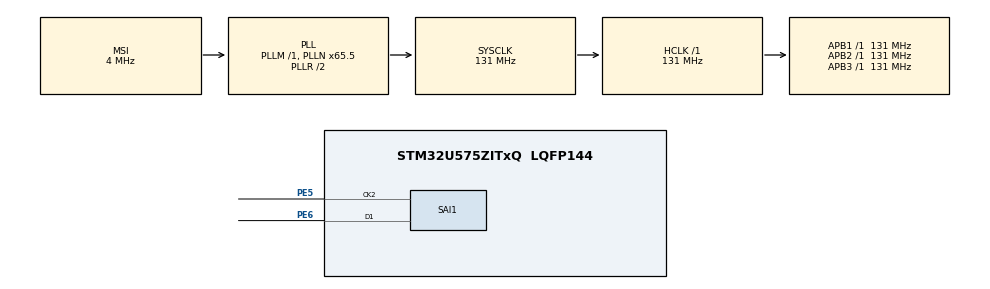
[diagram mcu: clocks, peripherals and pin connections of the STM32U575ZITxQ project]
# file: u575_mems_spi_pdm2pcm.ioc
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CORTEX_M33_NS.userName=CORTEX_M33
GPDMA1.CIRCULARMODE_GPDMACH0=ENABLE
GPDMA1.DESTINC_GPDMACH0=DMA_DINC_INCREMENTED
GPDMA1.IPHANDLE_GPDMACH0-SIMPLEREQUEST_GPDMACH0=__NULL
GPDMA1.REQUEST_GPDMACH0=GPDMA1_REQUEST_SAI1_A
Mcu.Family=STM32U5
Mcu.Name=STM32U575ZITxQ
Mcu.Package=LQFP144
NVIC.GPDMA1_Channel0_IRQn=true\:0\:0\:false\:false\:true\:false\:true\:true
NVIC.PriorityGroup=NVIC_PRIORITYGROUP_4
PE5.Mode=PDM_Master_Mode_CK2
PE5.Signal=SAI1_CK2
PE6.Mode=PDM_Master_Mode_CK2
PE6.Signal=SAI1_D1
ProjectManager.HeapSize=0x200
ProjectManager.StackSize=0x400
ProjectManager.TargetToolchain=STM32CubeIDE
RCC.ADCFreq_Value=16000000
RCC.AHBFreq_Value=131000000
RCC.APB1Freq_Value=131000000
RCC.APB1TimFreq_Value=131000000
RCC.APB2Freq_Value=131000000
RCC.APB2TimFreq_Value=131000000
RCC.APB3Freq_Value=131000000
RCC.CortexFreq_Value=131000000
RCC.EPOD_VALUE=4000000
RCC.HCLKFreq_Value=131000000
RCC.HSE_VALUE=16000000
RCC.HSI48_VALUE=48000000
RCC.HSI_VALUE=16000000
RCC.LSE_VALUE=32768
RCC.LSIDIV_VALUE=32000
RCC.MSI_VALUE=4000000
RCC.PLL2N=80
RCC.PLLFRACN=4096
RCC.PLLN=65
RCC.SPI1CLockSelection=RCC_SPI1CLKSOURCE_PCLK2
RCC.SYSCLKFreq_VALUE=131000000
RCC.SYSCLKSource=RCC_SYSCLKSOURCE_PLLCLK
RCC.USBFreq_Value=48000000
RCC.VCOOutputFreq_Value=262000000
SAI1.Activation=ENABLE
SAI1.ErrorAudioFreq-PDM_Master_Mode_CK2=62.76 %
SAI1.FSPolarity-PDM_Master_Mode_CK2=SAI_FS_ACTIVE_HIGH
SAI1.FrameLength-PDM_Master_Mode_CK2=16
SAI1.Instance-PDM_Master_Mode_CK2=SAI$Index_Block_A
SAI1.MckOutput-PDM_Master_Mode_CK2=SAI_MCK_OUTPUT_DISABLE
SAI1.MonoStereoMode-PDM_Master_Mode_CK2=SAI_STEREOMODE
SAI1.RealAudioFreq-PDM_Master_Mode_CK2=312.5 KHz
SAI1.SlotActive-PDM_Master_Mode_CK2=0x00000001
SAI1.SlotNumber-PDM_Master_Mode_CK2=2
SAI1.VirtualMode-PDM_Master_Mode_CK2=VM_MASTER
SAI1.VirtualProtocol-PDM_Master_Mode_CK2=VM_PDM_PROTOCOL
SAI1.VirtualSlotActive-PDM_Master_Mode_CK2=SAI_SLOT_USERSETTING
SAI1.VirtualSlotActive0-PDM_Master_Mode_CK2=true
VP_CRC_VS_CRC.Mode=CRC_Activate
VP_GPDMA1_VS_GPDMACH0.Mode=SIMPLEREQUEST_GPDMACH0
VP_LPBAMQUEUE_VS_QUEUE.Mode=QUEUEMODE
VP_LPBAM_VS_SIG1.Mode=SmartRun
VP_LPBAM_VS_SIG4.Mode=LPDMA1
VP_MEMORYMAP_VS_MEMORYMAP.Mode=CurAppReg
VP_PWR_VS_SECSignals.Mode=Security/Privilege
board=custom

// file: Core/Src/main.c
/* USER CODE BEGIN Header */
/**
 ******************************************************************************
 * @file           : main.c
 * @brief          : Main program body
 ******************************************************************************
 * @attention
 *
 * Copyright (c) 2024 STMicroelectronics.
 * All rights reserved.
 *
 * This software is licensed under terms that can be found in the LICENSE file
 * in the root directory of this software component.
 * If no LICENSE file comes with this software, it is provided AS-IS.
 *
 ******************************************************************************
 */
/* USER CODE END Header */
#include "main.h"

/* USER CODE BEGIN Includes */
#include "pdm2pcm.h"
/* USER CODE END Includes */

/* USER CODE BEGIN PD */

// output buffer buffer step in bytes

// input buffer in bytes 48samples * 64 decimation / 8bits
#define STEP_IN (STEP_OUT * 64 / 8)

#define PCM_SIZE 16384 * STEP_OUT

/* USER CODE END PD */

CRC_HandleTypeDef hcrc;

SAI_HandleTypeDef hsai_BlockA1;
DMA_NodeTypeDef Node_GPDMA1_Channel0;
DMA_QListTypeDef List_GPDMA1_Channel0;
DMA_HandleTypeDef handle_GPDMA1_Channel0;

/* USER CODE BEGIN PV */
extern PDM_Filter_Handler_t PDM1_filter_handler;

uint8_t u8SpiRxBuf[STEP_IN * 2];

uint16_t u16PcmBuf[PCM_SIZE];

uint32_t input_ptr = 0;
uint32_t output_ptr = 0;
uint32_t i;
uint32_t ret_val;
/* USER CODE END PV */

void SystemClock_Config(void);
static void MX_GPIO_Init(void);
static void MX_GPDMA1_Init(void);
static void MX_CRC_Init(void);
static void MX_SAI1_Init(void);

/* USER CODE BEGIN 0 */
// void HAL_SPI_RxHalfCpltCallback(SPI_HandleTypeDef *hspi)
void HAL_SAI_RxHalfCpltCallback(SAI_HandleTypeDef *hsai)
{
  ret_val = PDM_Filter((uint8_t *)(&u8SpiRxBuf[0]), &u16PcmBuf[output_ptr], &PDM1_filter_handler);
  output_ptr += STEP_OUT;
  if (output_ptr >= PCM_SIZE)
  {
    while (1)
      ;
  }
}
void HAL_SAI_RxCpltCallback(SAI_HandleTypeDef *hsai)
// void HAL_SPI_RxCpltCallback(SPI_HandleTypeDef *hspi)
{
  ret_val = PDM_Filter((uint8_t *)(&u8SpiRxBuf[STEP_IN]), &u16PcmBuf[output_ptr], &PDM1_filter_handler);
  output_ptr += STEP_OUT;

  if (output_ptr >= PCM_SIZE)
  {
    while (1)
      ;
  }
}
/* USER CODE END 0 */

int main(void)
{

  /* MCU Configuration--------------------------------------------------------*/

  /* Reset of all peripherals, Initializes the Flash interface and the Systick. */
  HAL_Init();

  /* Configure the system clock */
  SystemClock_Config();

  /* Initialize all configured peripherals */
  MX_GPIO_Init();
  MX_GPDMA1_Init();
  MX_CRC_Init();
  MX_SAI1_Init();
  /* USER CODE BEGIN 2 */
  MX_CRC_Init();
  /* USER CODE BEGIN 2 */
  MX_PDM2PCM_Init();

  // HAL_SPI_Receive_DMA(&hspi1, u8SpiRxBuf, STEP_IN * 2);
  HAL_SAI_Receive_DMA(&hsai_BlockA1, u8SpiRxBuf, STEP_IN * 2);
  /* USER CODE END 2 */

  /* Infinite loop */
  while (1)
  {

  }
}

void SystemClock_Config(void)
{
  RCC_OscInitTypeDef RCC_OscInitStruct = {0};
  RCC_ClkInitTypeDef RCC_ClkInitStruct = {0};

  /** Configure the main internal regulator output voltage
  */
  if (HAL_PWREx_ControlVoltageScaling(PWR_REGULATOR_VOLTAGE_SCALE1) != HAL_OK)
  {
    Error_Handler();
  }

  /** Initializes the CPU, AHB and APB buses clocks
  */
  RCC_OscInitStruct.OscillatorType = RCC_OSCILLATORTYPE_MSI;
  RCC_OscInitStruct.MSIState = RCC_MSI_ON;
  RCC_OscInitStruct.MSICalibrationValue = RCC_MSICALIBRATION_DEFAULT;
  RCC_OscInitStruct.MSIClockRange = RCC_MSIRANGE_4;
  RCC_OscInitStruct.PLL.PLLState = RCC_PLL_ON;
  RCC_OscInitStruct.PLL.PLLSource = RCC_PLLSOURCE_MSI;
  RCC_OscInitStruct.PLL.PLLMBOOST = RCC_PLLMBOOST_DIV1;
  RCC_OscInitStruct.PLL.PLLM = 1;
  RCC_OscInitStruct.PLL.PLLN = 65;
  RCC_OscInitStruct.PLL.PLLP = 2;
  RCC_OscInitStruct.PLL.PLLQ = 2;
  RCC_OscInitStruct.PLL.PLLR = 2;
  RCC_OscInitStruct.PLL.PLLRGE = RCC_PLLVCIRANGE_0;
  RCC_OscInitStruct.PLL.PLLFRACN = 4096;
  if (HAL_RCC_OscConfig(&RCC_OscInitStruct) != HAL_OK)
  {
    Error_Handler();
  }

  /** Initializes the CPU, AHB and APB buses clocks
  */
  RCC_ClkInitStruct.ClockType = RCC_CLOCKTYPE_HCLK|RCC_CLOCKTYPE_SYSCLK
                              |RCC_CLOCKTYPE_PCLK1|RCC_CLOCKTYPE_PCLK2
                              |RCC_CLOCKTYPE_PCLK3;
  RCC_ClkInitStruct.SYSCLKSource = RCC_SYSCLKSOURCE_PLLCLK;
  RCC_ClkInitStruct.AHBCLKDivider = RCC_SYSCLK_DIV1;
  RCC_ClkInitStruct.APB1CLKDivider = RCC_HCLK_DIV1;
  RCC_ClkInitStruct.APB2CLKDivider = RCC_HCLK_DIV1;
  RCC_ClkInitStruct.APB3CLKDivider = RCC_HCLK_DIV1;

  if (HAL_RCC_ClockConfig(&RCC_ClkInitStruct, FLASH_LATENCY_4) != HAL_OK)
  {
    Error_Handler();
  }
}

static void MX_CRC_Init(void)
{

  hcrc.Instance = CRC;
  hcrc.Init.DefaultPolynomialUse = DEFAULT_POLYNOMIAL_ENABLE;
  hcrc.Init.DefaultInitValueUse = DEFAULT_INIT_VALUE_ENABLE;
  hcrc.Init.InputDataInversionMode = CRC_INPUTDATA_INVERSION_NONE;
  hcrc.Init.OutputDataInversionMode = CRC_OUTPUTDATA_INVERSION_DISABLE;
  hcrc.InputDataFormat = CRC_INPUTDATA_FORMAT_BYTES;
  if (HAL_CRC_Init(&hcrc) != HAL_OK)
  {
    Error_Handler();
  }

}

static void MX_GPDMA1_Init(void)
{

  /* Peripheral clock enable */
  __HAL_RCC_GPDMA1_CLK_ENABLE();

  /* GPDMA1 interrupt Init */
    HAL_NVIC_SetPriority(GPDMA1_Channel0_IRQn, 0, 0);
    HAL_NVIC_EnableIRQ(GPDMA1_Channel0_IRQn);

}

static void MX_SAI1_Init(void)
{

  hsai_BlockA1.Instance = SAI1_Block_A;
  hsai_BlockA1.Init.Protocol = SAI_FREE_PROTOCOL;
  hsai_BlockA1.Init.AudioMode = SAI_MODEMASTER_RX;
  hsai_BlockA1.Init.DataSize = SAI_DATASIZE_8;
  hsai_BlockA1.Init.FirstBit = SAI_FIRSTBIT_MSB;
  hsai_BlockA1.Init.ClockStrobing = SAI_CLOCKSTROBING_FALLINGEDGE;
  hsai_BlockA1.Init.Synchro = SAI_ASYNCHRONOUS;
  hsai_BlockA1.Init.OutputDrive = SAI_OUTPUTDRIVE_DISABLE;
  hsai_BlockA1.Init.NoDivider = SAI_MASTERDIVIDER_ENABLE;
  hsai_BlockA1.Init.FIFOThreshold = SAI_FIFOTHRESHOLD_EMPTY;
  hsai_BlockA1.Init.AudioFrequency = 256000;
  hsai_BlockA1.Init.MckOutput = SAI_MCK_OUTPUT_DISABLE;
  hsai_BlockA1.Init.MonoStereoMode = SAI_STEREOMODE;
  hsai_BlockA1.Init.CompandingMode = SAI_NOCOMPANDING;
  hsai_BlockA1.Init.PdmInit.Activation = ENABLE;
  hsai_BlockA1.Init.PdmInit.MicPairsNbr = 1;
  hsai_BlockA1.Init.PdmInit.ClockEnable = SAI_PDM_CLOCK2_ENABLE;
  hsai_BlockA1.FrameInit.FrameLength = 16;
  hsai_BlockA1.FrameInit.ActiveFrameLength = 1;
  hsai_BlockA1.FrameInit.FSDefinition = SAI_FS_STARTFRAME;
  hsai_BlockA1.FrameInit.FSPolarity = SAI_FS_ACTIVE_HIGH;
  hsai_BlockA1.FrameInit.FSOffset = SAI_FS_FIRSTBIT;
  hsai_BlockA1.SlotInit.FirstBitOffset = 0;
  hsai_BlockA1.SlotInit.SlotSize = SAI_SLOTSIZE_DATASIZE;
  hsai_BlockA1.SlotInit.SlotNumber = 2;
  hsai_BlockA1.SlotInit.SlotActive = 0x00000001;
  if (HAL_SAI_Init(&hsai_BlockA1) != HAL_OK)
  {
    Error_Handler();
  }

}

static void MX_GPIO_Init(void)
{

  /* GPIO Ports Clock Enable */
  __HAL_RCC_GPIOE_CLK_ENABLE();

}

void Error_Handler(void)
{
  __disable_irq();
  while (1)
  {
  }
}
